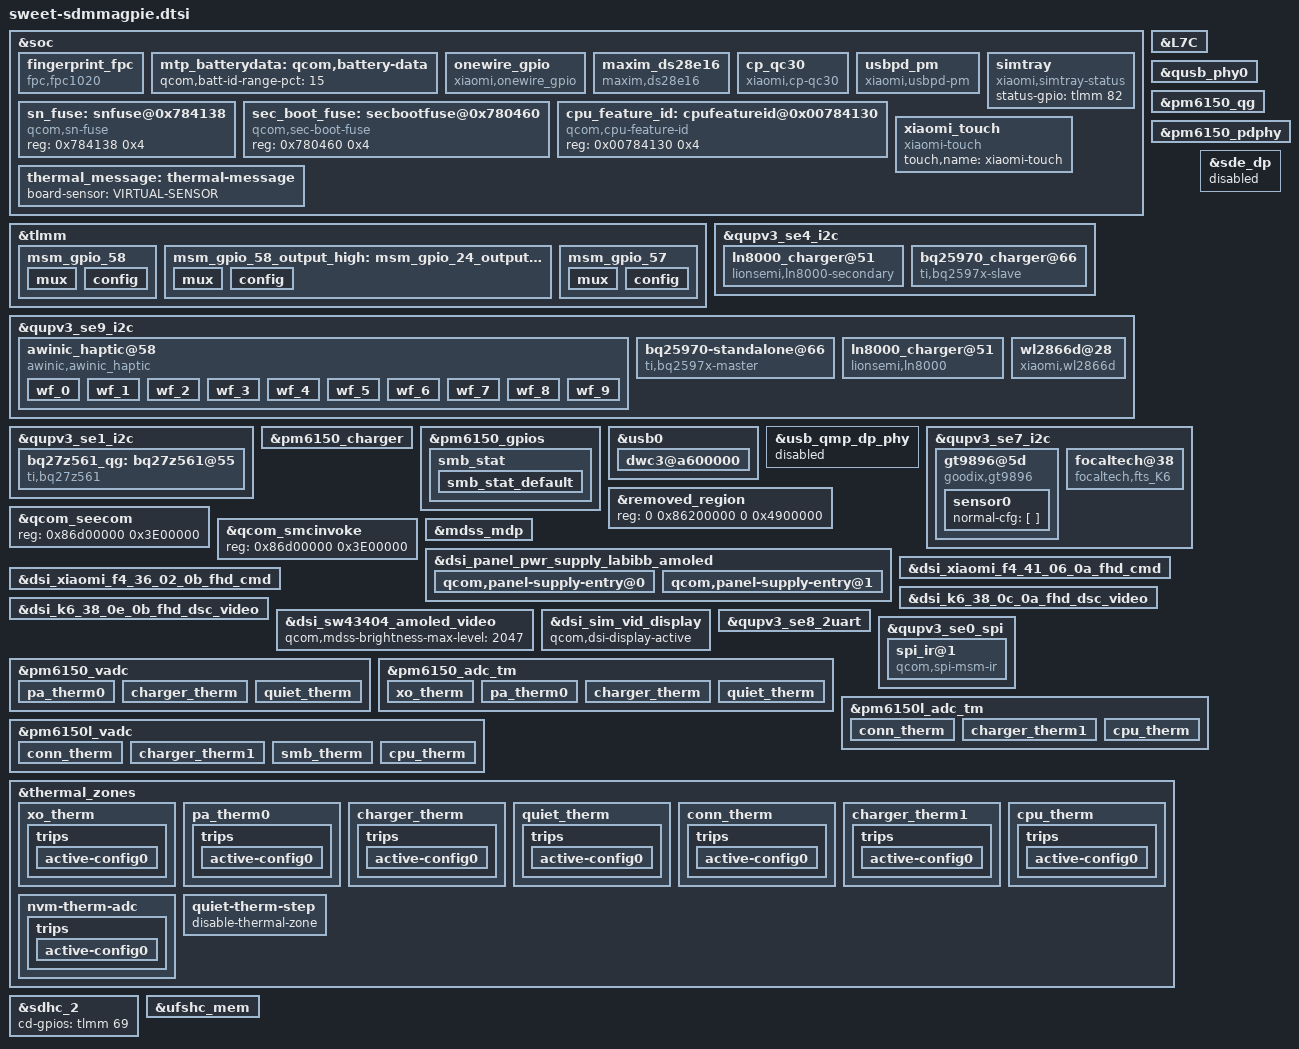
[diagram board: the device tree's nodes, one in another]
/*
this file is for attribution only of aquila
And public attribution of xiaomi platforms(like F3 and so and)
*/

#include "sweet-sdmmagpie-pinctrl.dtsi"
#include "xiaomi-sdmmagpie-common.dtsi"
#include "sweet-sdmmagpie-camera-sensor.dtsi"

&soc {
	/*
	touch_vddio_vreg: touch_vddio_vreg {
		compatible = "regulator-fixed";
		regulator-name = "disp_vddio_vreg";
		startup-delay-us = <4000>;
		enable-active-high;
		regulator-boot-on;
		gpio = <&tlmm 90 0>;
	};*/

	fingerprint_fpc {
		status = "ok";
		compatible = "fpc,fpc1020";
		interrupt-parent = <&tlmm>;
		interrupts = <57 0x0>;
		fpc,gpio_rst    = <&tlmm 58 0x0>;
		fpc,gpio_irq    = <&tlmm 57 0x0>;
		pinctrl-names = "fpc1020_reset_reset",
			"fpc1020_reset_active",
			"fpc1020_irq_active";

		pinctrl-0 = <&msm_gpio_58>;
		pinctrl-1 = <&msm_gpio_58_output_high>;
		pinctrl-2 = <&msm_gpio_57>;
	};

	mtp_batterydata: qcom,battery-data {
		qcom,batt-id-range-pct = <15>;
		#include "batterydata-K6-sunwoda-5020mah.dtsi"
		#include "batterydata-K6-nvt-5020mah.dtsi"
	};

	onewire_gpio: onewire_gpio{
		compatible = "xiaomi,onewire_gpio";
		label = "xm_onewire";
		xiaomi,version = <1>;
		xiaomi,ow_gpio = <&tlmm 91 0x00>;
		mi,onewire-gpio-cfg-addr = <0x0395B000 0x4>;
		pinctrl-names = "onewire_active", "onewire_sleep";
		pinctrl-0 = <&onewire_gpio_active>;
		pinctrl-1 = <&onewire_gpio_sleep>;
		status = "ok";
	};

	maxim_ds28e16: maxim_ds28e16{
		compatible = "maxim,ds28e16";
		label = "max_ds28e16";
		maxim,version = <1>;
		status = "ok";
	};

	cp_qc30 {
		compatible = "xiaomi,cp-qc30";
		status = "ok";
		mi,qc3-bat-volt-max = <4450>;
		mi,qc3-ffc-bat-volt-max = <4470>;
		mi,qc3-bat-curr-max = <5400>;
		mi,qc3-bus-volt-max = <12000>;
		mi,qc3-bus-curr-max = <2100>;
		mi,support-qc3p5-without-smb;
		mi,cp-sec-enable;
	};

	usbpd_pm {
		compatible = "xiaomi,usbpd-pm";
		status = "ok";
		mi,pd-bat-volt-max = <4450>;
		mi,pd-ffc-bat-volt-max = <4475>;
		mi,pd-bat-curr-max = <12000>;
		mi,pd-bus-volt-max = <12000>;
		mi,pd-bus-curr-max = <6100>;
		mi,pd-bus-curr-compensate = <300>;
		mi,cp-sec-enable;
	};

	simtray {
		compatible = "xiaomi,simtray-status";
		status-gpio = <&tlmm 82 0x00>;
	};

	sn_fuse: snfuse@0x784138 {
		compatible = "qcom,sn-fuse";
		reg = <0x784138 0x4>;
		reg-names = "sn-base";
	};

	sec_boot_fuse: secbootfuse@0x780460 {
		compatible = "qcom,sec-boot-fuse";
		reg = <0x780460  0x4>;
		reg-names = "sec-boot-base";
	};

	cpu_feature_id: cpufeatureid@0x00784130 {
		compatible = "qcom,cpu-feature-id";
		reg = <0x00784130  0x4>;
		reg-names = "cpu-feature-id";
	};
};

&L7C {
		regulator-min-microvolt = <3200000>;
		regulator-max-microvolt = <3200000>;
		qcom,init-voltage = <3200000>;
};

&tlmm {
	/* GPIO_58: FP_RESET_N */
	msm_gpio_58: msm_gpio_58 {
		mux {
			pins = "gpio58";
			function = "gpio";
		};
		config {
			pins = "gpio58";
			driver-strength = <2>;
			bias-disable;
			output-low;
		};
	};
	/* GPIO_58 : FP_RESET_N, state device active */
	msm_gpio_58_output_high: msm_gpio_24_output_high {
		mux {
			pins = "gpio58";
			function = "gpio";
		};
		config {
			pins = "gpio58";
			drive-strength = <2>;
			bias-disable;
			output-high;
		};
	};
	/* GPIO_57 : FP_INT_N */
	msm_gpio_57: msm_gpio_57 {
		mux {
			pins = "gpio57";
			function = "gpio";
		};
		config {
			pins = "gpio57";
			drive-strength = <2>;
			bias-pull-down;
		};
	};

};

&qusb_phy0 {
	qcom,qusb-phy-init-seq =
		/* <value reg_offset> */
		   <0x23 0x210 /* PWR_CTRL1 */
		    0x03 0x04  /* PLL_ANALOG_CONTROLS_TWO */
		    0x7c 0x18c /* PLL_CLOCK_INVERTERS */
		    0x80 0x2c  /* PLL_CMODE */
		    0x0a 0x184 /* PLL_LOCK_DELAY */
		    0x19 0xb4  /* PLL_DIGITAL_TIMERS_TWO */
		    0x40 0x194 /* PLL_BIAS_CONTROL_1 */
		    0x16 0x198 /* PLL_BIAS_CONTROL_2 */
		    0x21 0x214 /* PWR_CTRL2 */
		    0x08 0x220 /* IMP_CTRL1 */
		    0x58 0x224 /* IMP_CTRL2 */
		    0x07 0x240 /* TUNE1 */
		    0x29 0x244 /* TUNE2 */
		    0xca 0x248 /* TUNE3 */
		    0x07 0x24c /* TUNE4 */
		    0x03 0x250 /* TUNE5 */
		    0x30 0x23c /* CHG_CTRL2 */
		    0x22 0x210>; /* PWR_CTRL1 */
};

&qupv3_se4_i2c {
	status = "ok";
	ln8000_charger@51 {
		compatible = "lionsemi,ln8000-secondary";
		reg = <0x51>;
		/* bank <bit-idx> <flags: active-low> */
		//irq-gpios = <&tlmm 55 0x2002>;
        //interrupt-parent = <&tlmm>;
        //interrupts = <55 0x2002>;
        //pinctrl-names = "default";
        //pinctrl-0 = <&bq2597x_int_default &bq2597x_int_suspend>;
		ln8000_charger,irq_index = <296>;
		/* device configuration */
		ln8000_charger,bat-ovp-threshold = <4560>;
        ln8000_charger,bat-ovp-alarm-threshold = <4525>;
        ln8000_charger,bus-ovp-threshold = <13000>;
        ln8000_charger,bus-ovp-alarm-threshold = <11000>;
        ln8000_charger,bus-ocp-threshold = <3750>;
        ln8000_charger,bus-ocp-alarm-threshold = <3500>;
        ln8000_charger,ntc-alarm-cfg  = <226>;
		/* protection enable/disable flags
		 *   vbat-ovp-disable
		 *   vbat-reg-disable
		 *   iin-ocp-disable
		 *   iin-reg-disable
		 *   tbus-mon-disable
		 *   tbat-mon-disable
		 *   tdie-prot-disable
		 *   tdie-reg-disable
		 *   revcurr-prot-disable
		 */
		ln8000_charger,tdie-prot-disable;
        ln8000_charger,tbus-mon-disable;
        ln8000_charger,tbat-mon-disable;
        ln8000_charger,iin-ocp-disable;
        ln8000_charger,iin-reg-disable;
        ln8000_charger,tdie-reg-disable;
        ln8000_charger,vbat-reg-disable;
	};

	bq25970_charger@66 {
		compatible = "ti,bq2597x-slave";
		reg = <0x66>;

		interrupt-parent = <&tlmm>;
		interrupts = <56 0x2002>;
		pinctrl-names = "default_2";
		pinctrl-0 = <&bq2597x_2_int_default &bq2597x_2_int_suspend>;

		/*ti,bq2597x,bat-ovp-disable;*/
		ti,bq2597x,bat-ovp-alarm-disable;
		ti,bq2597x,bat-ocp-disable;
		ti,bq2597x,bat-ocp-alarm-disable;
		ti,bq2597x,bat-ucp-alarm-disable;
		ti,bq2597x,bat-ucp-disable;

		/*ti,bq2597x,bus-ovp-alarm-disable;
		ti,bq2597x,bus-ocp-disable;
		ti,bq2597x,bus-ocp-alarm-disable;*/
		ti,bq2597x,bat-therm-disable;
		ti,bq2597x,bus-therm-disable;
		ti,bq2597x,die-therm-disable;

		ti,bq2597x,bat-ovp-threshold = <4575>;
		ti,bq2597x,bat-ovp-alarm-threshold = <4500>;
		//ti,bq2597x,bat-ocp-threshold = <5000>;
		//ti,bq2597x,bat-ocp-alarm-threshold = <4500>;

		ti,bq2597x,bus-ovp-threshold = <12000>;
		ti,bq2597x,bus-ovp-alarm-threshold = <11000>;
		ti,bq2597x,bus-ocp-threshold = <3500>;
		ti,bq2597x,bus-ocp-alarm-threshold = <3200>;

		//ti,bq2597x,bat-ucp-alarm-threshold = <2000>;

		ti,bq2597x,bat-therm-threshold = <0x15>;/*4.1%*/
		ti,bq2597x,bus-therm-threshold = <0x15>;/*4.1%*/
		ti,bq2597x,die-therm-threshold = <145>;

		ti,bq2597x,ac-ovp-threshold = <14>;
		//ti,bq2597x,sense-resistor-mohm = <2>;
	};
};

&qupv3_se9_i2c {
	status = "ok";
	qcom,clk-freq-out = <400000>;
	qcom,clk-freq-in = <400000>;
	awinic_haptic@58 {
		compatible = "awinic,awinic_haptic";
		reg = <0x5A>;
		aw8622x_i2c_addr = < 0x58 >;
		reset-gpio = <&tlmm 4 0>;
		irq-gpio = <&pm6150l_gpios  10 0>;
		pinctrl-names = "awinic_reset_reset","awinic_reset_active","awinic_interrupt_active";
		pinctrl-0 = <&awinic_gpio_reset>;
		pinctrl-1 = <&awinic_gpio_reset_output_high>;
		pinctrl-2 = <&awinic_gpio_int>;
		/*---------------------aw8624_dts_info---------------------*/
		aw8624_vib_f0_pre = < 2050 >;
		aw8624_vib_f0_cali_percen = < 7 >;
		aw8624_vib_cont_drv_lev = < 106 >;
		aw8624_vib_cont_drv_lvl_ov = < 155 >;
		aw8624_vib_cont_td = < 0xF06C >;
		aw8624_vib_cont_zc_thr = < 0x08F8 >;
		aw8624_vib_cont_num_brk = < 3 >;
		aw8624_vib_f0_coeff = < 260 >; /*Don't modify it*/
		aw8624_vib_duration_time = < 15 60 0 0 0 >;
		aw8624_vib_brake_ram_config = < 1 1 90 60 20 3 1 3 1 1 90 60 30 5 1 3 0 0 50 40 25 0 5 3 >;
		aw8624_vib_brake_cont_config = < 1 1 90 42 20 5 2 2 0 0 0 0 0 0 0 0 0 0 0 0 0 0 0 0 >;
		aw8624_vib_f0_trace_parameter = < 9 5 1 15 >;
		aw8624_vib_bemf_config = < 0 8 3 0xf8 >;
		aw8624_vib_sw_brake = < 0x2c >;
		aw8624_vib_wavseq = < 0 1 1 2 0 0 0 0 0 0 0 0 0 0 0 0 >; /*wavseq1-seq8 0x07-0x0E*/
		aw8624_vib_wavloop = < 0 6 1 15 0 0 0 0 0 0>;/*loop1-mainloog 0x0f-0x13*/
		aw8624_vib_td_brake = < 42720 42720 42720 >; /*level0 level1 level2*/
		aw8624_vib_tset = < 0x11 >;
		aw8624_vib_func_parameter1 = < 1 >;
		aw8624_vib_gain_flag = < 1 >;
		aw8624_vib_r_spare = < 0x68 >;
		aw8624_vib_bstdbg = < 0x30 0xeb 0xd4 0 0 0 >;
		/*---------------------aw8622x_dts_info---------------------*/
		aw8622x_vib_mode = < 0 >; /* mode: RAM mode->0; CONT mode->1 */
		aw8622x_vib_f0_pre = < 2050 >;
		aw8622x_vib_f0_cali_percen = < 7 >;
		aw8622x_vib_cont_drv1_lvl = < 0x7F >;
		aw8622x_vib_cont_drv2_lvl = < 0x3A >;
		aw8622x_vib_cont_brk_time = < 0x06 >;
		aw8622x_vib_cont_tset = < 0x06 >;
		aw8622x_vib_cont_bemf_set = < 0x02 >;
		aw8622x_vib_cont_drv_width = < 0x56 >;
		aw8622x_vib_cont_wait_num = < 0x06 >;
		aw8622x_vib_cont_brk_gain = < 0x08 >;
		aw8622x_vib_cont_drv1_time = < 0x08 >;
		aw8622x_vib_cont_drv2_time = < 0x14 >;
		aw8622x_vib_cont_track_margin = < 0x0F >;
		aw8622x_vib_sine_array = < 0x05 0xB2 0xFF 0xEF >; /* SIN_H SIN_L COS_H COS_L*/
		aw8622x_vib_d2s_gain = < 0x05 >;
		aw8622x_vib_prctmode = < 0x2D 0x3E 0x3F >;
		/*---------------------common_dts_info---------------------*/
		vib_effect_id_boundary = < 10 >;
		vib_effect_max = < 170 >;
		vib_rtp_time = < 20 20 20 20 20 20 20 20 20 30
				 40 50 60 70 80 90 100 110 120 130
				 140 150 160 170 180 190 200 210 220 230
				 240 250 260 270 280 290 300 310 320 330
				 20 20 20 20 20 20 20 20 20 20
				 20 20 20 20 20 20 20 20 20 20
				 20 20 20 20 20 20 20 20 20 20
				 20 20 20 20 20 20 20 20 20 20
				 20 20 20 20 20 20 20 20 20 20
				 20 20 20 20 20 20 20 20 20 20
				 20 20 20 20 20 20 20 20 20 20
				 20 20 20 20 20 20 20 20 20 20
				 20 20 20 20 20 20 20 20 20 20
				 20 20 20 20 20 20 20 20 20 20
				 20 20 20 20 20 20 20 20 20 20
				 20 20 20 20 20 20 20 20 20 20
				 20 20 20 20 20 20 20 20 20 20
				 20 20 20 20 20 >;
		status = "okay";
		wf_0 {
			//CLICK
			qcom,effect-id = <0>;
			qcom,wf-vmax-mv = <3600>;
			qcom,wf-pattern = [3e 3e];
			qcom,wf-brake-pattern = [02 01 00 00];
			qcom,wf-play-rate-us = <20000>;
		};
		wf_1 {
			//DOUBLE CLICK
			qcom,effect-id = <1>;
			qcom,wf-vmax-mv = <3600>;
			qcom,wf-pattern = [7e 3e];
			qcom,wf-brake-pattern = [03 01 00 00];
			qcom,wf-play-rate-us = <20000>;
		};
		wf_2 {
			//TICK
			qcom,effect-id = <2>;
			qcom,wf-vmax-mv = <3600>;
			qcom,wf-pattern = [7e 3e];
			qcom,wf-brake-pattern = [02 01 00 00];
			qcom,wf-play-rate-us = <20000>;
		};
		wf_3 {
			//THUD
			qcom,effect-id = <3>;
			qcom,wf-vmax-mv = <3600>;
			qcom,wf-pattern = [3e 3e];
			qcom,wf-brake-pattern = [02 01 00 00];
			qcom,wf-play-rate-us = <20000>;
		};
		wf_4 {
			//POP
			qcom,effect-id = <4>;
			qcom,wf-vmax-mv = <3600>;
			qcom,wf-pattern = [3e 3e];
			qcom,wf-brake-pattern = [02 01 00 00];
			qcom,wf-play-rate-us = <28000>;
		};
		wf_5 {
			//HEAVY CLICK
			qcom,effect-id = <5>;
			qcom,wf-vmax-mv = <3600>;
			qcom,wf-pattern = [7e 7e 7e];
			qcom,wf-brake-pattern = [03 03 01 00];
			qcom,wf-play-rate-us = <20000>;
		};
		wf_6 {
			//id 6
			qcom,effect-id = <6>;
			qcom,wf-vmax-mv = <3600>;
			qcom,wf-pattern = [3e 3e];
			qcom,wf-brake-pattern = [02 01 00 00];
			qcom,wf-play-rate-us = <20000>;
		};
		wf_7 {
			//id 7
			qcom,effect-id = <7>;
			qcom,wf-vmax-mv = <3600>;
			qcom,wf-pattern = [3e 3e];
			qcom,wf-brake-pattern = [02 01 00 00];
			qcom,wf-play-rate-us = <20000>;
		};
		wf_8 {
			//id 8
			qcom,effect-id = <8>;
			qcom,wf-vmax-mv = <3600>;
			qcom,wf-pattern = [3e 3e];
			qcom,wf-brake-pattern = [02 01 00 00];
			qcom,wf-play-rate-us = <20000>;
		};
		wf_9 {
			//id 9
			qcom,effect-id = <9>;
			qcom,wf-vmax-mv = <3600>;
			qcom,wf-pattern = [3e 3e];
			qcom,wf-brake-pattern = [02 01 00 00];
			qcom,wf-play-rate-us = <20000>;
		};
	};

	bq25970-standalone@66 {
		compatible = "ti,bq2597x-master";
		reg = <0x66>;

		interrupt-parent = <&tlmm>;
		interrupts = <55 0x2002>;
		pinctrl-names = "default";
		pinctrl-0 = <&bq2597x_int_default &bq2597x_int_suspend>;

		/*ti,bq2597x,bat-ovp-disable;*/
		ti,bq2597x,bat-ovp-alarm-disable;
		ti,bq2597x,bat-ocp-disable;
		ti,bq2597x,bat-ocp-alarm-disable;
		ti,bq2597x,bat-ucp-alarm-disable;
		ti,bq2597x,bat-ucp-disable;

		/*ti,bq2597x,bus-ovp-alarm-disable;
		ti,bq2597x,bus-ocp-disable;
		ti,bq2597x,bus-ocp-alarm-disable;*/
		ti,bq2597x,bat-therm-disable;
		ti,bq2597x,bus-therm-disable;
		ti,bq2597x,die-therm-disable;

		ti,bq2597x,bat-ovp-threshold = <4575>;
		ti,bq2597x,bat-ovp-alarm-threshold = <4500>;
		//ti,bq2597x,bat-ocp-threshold = <5000>;
		//ti,bq2597x,bat-ocp-alarm-threshold = <4500>;

		ti,bq2597x,bus-ovp-threshold = <12000>;
		ti,bq2597x,bus-ovp-alarm-threshold = <11000>;
		ti,bq2597x,bus-ocp-threshold = <3500>;
		ti,bq2597x,bus-ocp-alarm-threshold = <3200>;

		//ti,bq2597x,bat-ucp-alarm-threshold = <2000>;

		ti,bq2597x,bat-therm-threshold = <0x15>;/*4.1%*/
		ti,bq2597x,bus-therm-threshold = <0x15>;/*4.1%*/
		ti,bq2597x,die-therm-threshold = <145>;

		ti,bq2597x,ac-ovp-threshold = <14>;
		//ti,bq2597x,sense-resistor-mohm = <2>;
	};

	ln8000_charger@51 {
		compatible = "lionsemi,ln8000";
		reg = <0x51>;
		/* bank <bit-idx> <flags: active-low> */
		//irq-gpios = <&tlmm 55 0x2002>;

                //interrupt-parent = <&tlmm>;
                //interrupts = <55 0x2002>;
                //pinctrl-names = "default";
                //pinctrl-0 = <&bq2597x_int_default &bq2597x_int_suspend>;
		ln8000_charger,irq_index = <296>;
		/* device configuration */
		ln8000_charger,bat-ovp-threshold = <4560>;
        ln8000_charger,bat-ovp-alarm-threshold = <4525>;
        ln8000_charger,bus-ovp-threshold = <13000>;
        ln8000_charger,bus-ovp-alarm-threshold = <11000>;
        ln8000_charger,bus-ocp-threshold = <3750>;
        ln8000_charger,bus-ocp-alarm-threshold = <3500>;
        ln8000_charger,ntc-alarm-cfg  = <226>;
		/* protection enable/disable flags
		 *   vbat-ovp-disable
		 *   vbat-reg-disable
		 *   iin-ocp-disable
		 *   iin-reg-disable
		 *   tbus-mon-disable
		 *   tbat-mon-disable
		 *   tdie-prot-disable
		 *   tdie-reg-disable
		 *   revcurr-prot-disable
		 */
		ln8000_charger,tdie-prot-disable;
        ln8000_charger,tbus-mon-disable;
        ln8000_charger,tbat-mon-disable;
        ln8000_charger,iin-ocp-disable;
        ln8000_charger,iin-reg-disable;
        ln8000_charger,tdie-reg-disable;
        ln8000_charger,vbat-reg-disable;
	};

    wl2866d@28 {
        compatible = "xiaomi,wl2866d";
        reg = <0x28>;
        vin1-supply = <&S8C>;
        vin1-voltage-level = <1350000  1350000>;
        vin2-supply = <&BOB>;
        vin2-voltage-level = <3300000  3300000>;
        en-gpio =  <&tlmm 30 0>;
        status = "ok";
    };
};

&pm6150_qg {
	qcom,battery-data = <&mtp_batterydata>;
	qcom,vbatt-cutoff-mv = <3400>;
	qcom,vbatt-low-mv = <3500>;
	qcom,vbatt-low-cold-mv = <3800>;
	qcom,vbatt-empty-mv = <3100>;
	qcom,vbatt-empty-cold-mv = <3000>;
	qcom,s3-entry-fifo-length = <2>;
	qcom,s3-entry-ibat-ua = <25000>;
	qcom,s3-exit-ibat-ua = <45000>;
	qcom,qg-iterm-ma = <350>;
	qcom,hold-soc-while-full;
	qcom,linearize-soc;
	qcom,cl-feedback-on;
	qcom,shutdown-soc-threshold = <10>;
	qcom,qg-ext-sns;
	mi,software-optimize-ffc-qg-iterm;
	qcom,shutdown-delay-enable;
	qcom,tcss-enable;
	qcom,tcss-entry-soc = <90>;
	qcom,bass-enable;
	qcom,esr-disable;

	qcom,soc_decimal_rate = <
		0  32
		10 30
		20 28
		30 28
		40 28
		50 28
		60 28
		70 28
		80 28
		90 26
		95 10
		99 5>;
};

&qupv3_se1_i2c {
	status = "ok";
    bq27z561_qg: bq27z561@55 {
        #io-channel-cells = <1>;
        compatible = "ti,bq27z561";
        bq,shutdown-delay-enable;
        reg = <0x55>;
        bq,soc_decimal_rate = <
				0  32
				10 30
				20 28
				30 28
				40 28
				50 28
				60 28
				70 28
				80 28
				90 26
				95 10
				99 5>;
	};
};

&pm6150_charger {
	io-channels = <&pm6150_vadc ADC_USB_IN_V_16>,
		      <&pm6150_vadc ADC_USB_IN_I>,
		      <&pm6150_vadc ADC_CHG_TEMP>,
		      <&pm6150_vadc ADC_DIE_TEMP>,
		      <&pm6150l_vadc ADC_AMUX_THM1_PU2>,
		      <&pm6150_vadc ADC_SBUx>,
		      <&pm6150_vadc ADC_VPH_PWR>;
	io-channel-names = "usb_in_voltage",
			   "usb_in_current",
			   "chg_temp",
			   "die_temp",
			   "conn_temp",
			   "sbux_res",
			   "vph_voltage";
	qcom,battery-data = <&mtp_batterydata>;
	qcom,usb-icl-ua = <3000000>;
	qcom,otg-cl-ua = <1500000>;
	qcom,fcc-max-ua = <12000000>;
	mi,fcc-batt-unverify-ua = <12200000>;
	qcom,fv-max-uv = <4480000>;
	qcom,auto-recharge-vbat-mv = <4400>;
	qcom,chg-term-src = <1>;
	qcom,chg-term-current-ma = <(-210)>;
	qcom,sec-charger-config = <0>;
	qcom,disable-sw-thermal-regulation;

	qcom,thermal-mitigation
				= <12400000 12000000 11500000 11000000 10500000 10000000 9500000
				   9000000  8500000  8000000  7500000  7000000  6500000  6000000
				   5500000  5000000  4500000  4000000  3500000  3000000  2500000
				   2000000  1500000  1000000  500000   0000000  0000000  0000000>;
	qcom,thermal-mitigation-icl
				= <12400000 12000000 11500000 11000000 10500000 10000000 9500000
				   9000000  8500000  8000000  7500000  7000000  6500000  6000000
				   5500000  5000000  4500000  4000000  3500000  3000000  2500000
				   2000000  1500000  1000000  500000   0000000  0000000  0000000>;
	qcom,thermal-mitigation-dcp
				= <12400000 12000000 11500000 11000000 10500000 10000000 9500000
				   9000000  8500000  8000000  7500000  7000000  6500000  6000000
				   5500000  5000000  4500000  4000000  3500000  3000000  2500000
				   2000000  1500000  1000000  500000   0000000  0000000  0000000>;
	qcom,thermal-mitigation-qc2
				= <12400000 12000000 11500000 11000000 10500000 10000000 9500000
				   9000000  8500000  8000000  7500000  7000000  6500000  6000000
				   5500000  5000000  4500000  4000000  3500000  3000000  2500000
				   2000000  1500000  1000000  500000   0000000  0000000  0000000>;
	qcom,thermal-fcc-qc3-normal
				= <12400000 12000000 11500000 11000000 10500000 10000000 9500000
				   9000000  8500000  8000000  7500000  7000000  6500000  6000000
				   5500000  5000000  4500000  4000000  3500000  3000000  2500000
				   2000000  1500000  1000000  500000   0000000  0000000  0000000>;
	qcom,thermal-fcc-qc3-cp
				= <12400000 12000000 11500000 11000000 10500000 10000000 9500000
				   9000000  8500000  8000000  7500000  7000000  6500000  6000000
				   5500000  5000000  4500000  4000000  3500000  3000000  2500000
				   2000000  1500000  1000000  500000   0000000  0000000  0000000>;
	qcom,thermal-mitigation-pd-base
				= <12400000 12000000 11500000 11000000 10500000 10000000 9500000
				   9000000  8500000  8000000  7500000  7000000  6500000  6000000
				   5500000  5000000  4500000  4000000  3500000  3000000  2500000
				   2000000  1500000  1000000  500000   0000000  0000000  0000000>;
	qcom,thermal-fcc-pps-cp
				= <12400000 12000000 11500000 11000000 10500000 10000000 9500000
				   9000000  8500000  8000000  7500000  7000000  6500000  6000000
				   5500000  5000000  4500000  4000000  3500000  3000000  2500000
				   2000000  1500000  1000000  500000   0000000  0000000  0000000>;

	dpdm-supply = <&qusb_phy0>;
	qcom,reg-dump-enable;
	qcom,sw-jeita-enable;
	qcom,step-charging-enable;
	/*qcom,distinguish-qc-class-ab;*/
	qcom,lpd-disable;
	qcom,usbpd-phandle = <&pm6150_pdphy>;
	qcom,disable-suspend-on-collapse;
	mi,use-bq-pump;
	mi,support-ffc;
	mi,early-status-report;
	mi,support-qc3p5-without-smb;
	mi,ffc-low-tbat = <150>;
	mi,ffc-high-tbat = <480>;
};

&pm6150_pdphy {
	mi,non-qcom-pps-ctrl;
	mi,pd_curr_limit = <1>;
	mi,pd_max_curr_limit = <6200000>;
	mi,limit_pd_unverified_pps_vbus = <1>;
	mi,pd_unverified_pps_max_vbus_limit = <9500000>;
};

&pm6150_gpios {
	smb_stat {
		smb_stat_default: smb_stat_default {
			pins = "gpio3";
			function = "normal";
			input-enable;
			bias-pull-up;
			qcom,pull-up-strength = <PMIC_GPIO_PULL_UP_30>;
			power-source = <0>;
		};
	};
/*
	vbus_disable {
		vbus_disable_suspend: usb_vbus_suspend {
			pins = "gpio4";
			function = "normal";
			output-low;
			power-source = <0>;
		};
	};
*/
};

&usb0 {
	dwc3@a600000 {
		usb-phy = <&qusb_phy0>, <&usb_nop_phy>;
		maximum-speed = "high-speed";
	};
};

&usb_qmp_dp_phy {
	status = "disabled";
};

&qupv3_se7_i2c{
	status = "ok";
	gt9896@5d {
		compatible = "goodix,gt9896";
		reg = <0x5d>;
		status = "ok";
		interrupt-parent = <&tlmm>;
		interrupts = <9 0x0>;
		pinctrl-names = "pmx_ts_active", "pmx_ts_suspend";
		pinctrl-0 = <&ts_active>;
		pinctrl-1 = <&ts_int_suspend &ts_reset_suspend>;
		vtouch-supply = <&pm6150l_l7>;
		goodix,vdd-gpio = <&tlmm 90 0x0>;
		goodix,avdd-name = "vtouch";
		goodix,reset-gpio = <&tlmm 8 0x0>;
		goodix,irq-gpio = <&tlmm 9 0x0>;
		goodix,irq-flags = <2>; /* 1:rising, 2:falling;*/
		goodix,panel-max-id = <10>;
		goodix,panel-max-x = <8639>;
		goodix,panel-max-y = <19199>;
		goodix,panel-max-w = <256>;
		goodix,panel-max-p = <256>;
		/*goodix,input-max-x = <1079>; */
		/*goodix,input-max-y = <2399>; */
		/*goodix,panel-key-map = <158 172 217>;*/ /*BACK,HOMEPAGE,SEARCH*/
		goodix,power-on-delay-us = <100>; /*0.1ms*/
		goodix,power-off-delay-us = <5000>;
		goodix,firmware-version = "6885b1";
		goodix,config-version = "6885v9c";
		/*goodix,swap-axis;*/
		/*goodix,x2x;*/
		/*goodix,y2y;*/
		/*goodix,pen-enable;*/
		/*goodix,key-of-pen = <331 332>;*//*BTN_STYLUS, BTN_STYLUS2*/
		tpd-filter-enable = <1>;
		tpd-filter-pixel-density = <161>;
		tpd-filter-custom-prameters = <0 0 0 0 0 0 0 0 0 0 0 0>;
		tpd-filter-custom-speed = <0 0 0>;
		/*new touch faeature default param*/
		goodix,touch-game-param-config1 = <3 3 1 3>;
		goodix,touch-game-param-config2 = <2 4 2 3>;
		goodix,touch-game-param-config3 = <4 4 3 1>;
		sensor0 {
			normal-cfg = [
			];
		};
	};
	focaltech@38{
		compatible = "focaltech,fts_K6";
		reg = <0x38>;
		interrupt-parent = <&tlmm>;
		interrupts = <9 0x0>;
		vdd-supply = <&pm6150l_l7>;
		vcc_i2c-supply = <&tlmm 90 0x0>;
		focaltech,reset-gpio = <&tlmm 8 0x0>;
		focaltech,irq-gpio = <&tlmm 9 0x0>;
		focaltech,max-touch-number = <10>;
		focaltech,display-coords =  <0 0 1079 2399>;
		pinctrl-names = "pmx_ts_active","pmx_ts_suspend","pmx_ts_release";
		pinctrl-0 = <&ts_active>;
		pinctrl-1 = <&ts_int_suspend &ts_reset_suspend>;
		pinctrl-2 = <&ts_release>;
		focaltech,touch-range-array = <1 5 10 15 20>;
		focaltech,touch-def-array = <3 3 3 3>;
		focaltech,touch-expert-array = <10 10 10 10
						20 20 15 10
						20 20 20 10>;

		/*
		focaltech,have-key;
		focaltech,key-number = <3>;
		focaltech,keys = <139 102 158>;
		focaltech,key-x-coords = <200 600 800>;
		focaltech,key-y-coords = <2000 2000 2000>;
		*/
	};
};

&soc {
	xiaomi_touch {
		compatible = "xiaomi-touch";
		status = "ok";
		touch,name = "xiaomi-touch";
	};
	thermal_message: thermal-message {
		board-sensor = "VIRTUAL-SENSOR";
	};
};

/* Enlarge TZ memory size to 62M */
&removed_region {
	reg = <0 0x86200000 0 0x4900000>;
};

&qcom_seecom {
	reg = <0x86d00000 0x3E00000>;
};

&qcom_smcinvoke {
	reg = <0x86d00000 0x3E00000>;
};

&sde_dp {
	status = "disabled";
	qcom,dp-usbpd-detection = <&pm6150_pdphy>;
};

&mdss_mdp {
	connectors = <&sde_rscc &sde_wb &sde_dsi &sde_dsi1>;
};

&dsi_panel_pwr_supply_labibb_amoled {

	qcom,panel-supply-entry@0 {
		reg = <0>;
		qcom,supply-name = "vddio";
		qcom,supply-min-voltage = <1900000>;
		qcom,supply-max-voltage = <1900000>;
		qcom,supply-enable-load = <32000>;
		qcom,supply-disable-load = <80>;
		qcom,supply-pre-off-sleep = <20>;
	};

	qcom,panel-supply-entry@1 {
		reg = <1>;
		qcom,supply-name = "vdda-3p3";
		qcom,supply-min-voltage = <3000000>;
		qcom,supply-max-voltage = <3000000>;
		qcom,supply-enable-load = <13200>;
		qcom,supply-disable-load = <80>;
		qcom,supply-pre-off-sleep = <10>;
	};
};

&dsi_xiaomi_f4_41_06_0a_fhd_cmd {
	qcom,panel-supply-entries = <&dsi_panel_pwr_supply_labibb_amoled>;
	qcom,mdss-dsi-bl-pmic-control-type = "bl_ctrl_dcs";
	qcom,mdss-dsi-bl-min-level = <2>;
	qcom,mdss-dsi-bl-max-level = <2047>;
	qcom,mdss-dsi-mode-sel-gpio-state = "single_port";
	//qcom,panel-mode-gpio = <&tlmm 7 0>;
	qcom,platform-te-gpio = <&tlmm 10 0>;
	qcom,platform-reset-gpio = <&pm6150l_gpios 9 0>;
};

&dsi_xiaomi_f4_36_02_0b_fhd_cmd {
	qcom,panel-supply-entries = <&dsi_panel_pwr_supply_labibb_amoled>;
	qcom,mdss-dsi-bl-pmic-control-type = "bl_ctrl_dcs";
	qcom,mdss-dsi-bl-min-level = <2>;
	qcom,mdss-dsi-bl-max-level = <2047>;
	qcom,mdss-dsi-mode-sel-gpio-state = "single_port";
	//qcom,panel-mode-gpio = <&tlmm 7 0>;
	qcom,platform-te-gpio = <&tlmm 10 0>;
	qcom,platform-reset-gpio = <&pm6150l_gpios 9 0>;
};

&dsi_k6_38_0c_0a_fhd_dsc_video {
	qcom,panel-supply-entries = <&dsi_panel_pwr_supply_labibb_amoled>;
	qcom,mdss-dsi-bl-pmic-control-type = "bl_ctrl_dcs";
	qcom,mdss-dsi-bl-min-level = <4>;
	qcom,mdss-dsi-bl-max-level = <2047>;
	qcom,mdss-brightness-max-level = <2047>;
	qcom,mdss-dsi-mode-sel-gpio-state = "single_port";
	//qcom,platform-en-gpio = <&tlmm 30 0>;
	qcom,platform-te-gpio = <&tlmm 10 0>;
	qcom,platform-reset-gpio = <&pm6150l_gpios 9 0>;
};

&dsi_k6_38_0e_0b_fhd_dsc_video {
	qcom,panel-supply-entries = <&dsi_panel_pwr_supply_labibb_amoled>;
	qcom,mdss-dsi-bl-pmic-control-type = "bl_ctrl_dcs";
	qcom,mdss-dsi-bl-min-level = <4>;
	qcom,mdss-dsi-bl-max-level = <2047>;
	qcom,mdss-brightness-max-level = <2047>;
	qcom,mdss-dsi-mode-sel-gpio-state = "single_port";
	//qcom,platform-en-gpio = <&tlmm 30 0>;
	qcom,platform-te-gpio = <&tlmm 10 0>;
	qcom,platform-reset-gpio = <&pm6150l_gpios 9 0>;
};

&dsi_sw43404_amoled_video {
	qcom,mdss-brightness-max-level = <2047>;
};

&dsi_sim_vid_display {
	qcom,dsi-display-active;
};

&qupv3_se8_2uart {
	status = "ok";
};

&qupv3_se0_spi {
	#address-cells = <1>;
	#size-cells = <0>;
		qcom,infinite-mode = <0>;
		qcom,usb-bam;
		qcom,rt-priority;
		qcom,use-pinctrl;
		qcom,ver-reg-exists;
		qcom,bam-consumer-pipe-index = <6>;
		qcom,bam-producer-pipe-index = <7>;
		qcom,master-id = <84>;
		status = "ok";
		spi_ir@1 {
			compatible = "qcom,spi-msm-ir";
			reg = <1>;
			spi-max-frequency = <50000000>;
			spi-cpol;
			status = "ok";
			};
};

&sde_dp {
        pinctrl-names = "mdss_dp_active", "mdss_dp_sleep";
        pinctrl-0 = <&sde_dp_aux_active &sde_dp_usbplug_cc_active>;
        pinctrl-1 = <&sde_dp_aux_suspend &sde_dp_usbplug_cc_suspend>;
        qcom,aux-en-gpio = <&tlmm 42 0>;
        qcom,aux-sel-gpio = <&tlmm 33 0>;
        qcom,dp-gpio-aux-switch;
};
&pm6150_vadc {
	pa_therm0 {
		reg = <ADC_AMUX_THM2_PU2>;
		label = "pa_therm0";
		qcom,ratiometric;
		qcom,hw-settle-time = <200>;
		qcom,pre-scaling = <1 1>;
	};

	charger_therm {
		reg = <ADC_AMUX_THM3_PU2>;
		label = "charger_therm";
		qcom,ratiometric;
		qcom,hw-settle-time = <200>;
		qcom,pre-scaling = <1 1>;
	};

	quiet_therm {
		reg = <ADC_AMUX_THM4_PU2>;
		label = "quiet_therm";
		qcom,ratiometric;
		qcom,hw-settle-time = <200>;
		qcom,pre-scaling = <1 1>;
	};
};

&pm6150_adc_tm {
	io-channels = <&pm6150_vadc ADC_XO_THERM_PU2>,
			<&pm6150_vadc ADC_AMUX_THM2_PU2>,
			<&pm6150_vadc ADC_AMUX_THM3_PU2>,
			<&pm6150_vadc ADC_AMUX_THM4_PU2>;

	/* Channel nodes */
	xo_therm {
		reg = <ADC_XO_THERM_PU2>;
		qcom,ratiometric;
		qcom,hw-settle-time = <200>;
	};

	pa_therm0 {
		reg = <ADC_AMUX_THM2_PU2>;
		qcom,ratiometric;
		qcom,hw-settle-time = <200>;
	};

	charger_therm {
		reg = <ADC_AMUX_THM3_PU2>;
		qcom,ratiometric;
		qcom,hw-settle-time = <200>;
	};

	quiet_therm {
		reg = <ADC_AMUX_THM4_PU2>;
		qcom,ratiometric;
		qcom,hw-settle-time = <200>;
	};
};

&pm6150l_vadc {
	conn_therm {
		reg = <ADC_AMUX_THM1_PU2>;
		label = "conn_therm";
		qcom,ratiometric;
		qcom,hw-settle-time = <200>;
		qcom,pre-scaling = <1 1>;
	};

	charger_therm1 {
		reg = <ADC_AMUX_THM2_PU2>;
		label = "charger_therm1";
		qcom,ratiometric;
		qcom,hw-settle-time = <200>;
		qcom,pre-scaling = <1 1>;
	};

	smb_therm {
		reg = <ADC_AMUX_THM2>;
		label = "smb_therm";
		qcom,hw-settle-time = <200>;
		qcom,pre-scaling = <1 1>;
	};

	cpu_therm {
		reg = <ADC_AMUX_THM3_PU2>;
		label = "cpu_therm";
		qcom,ratiometric;
		qcom,hw-settle-time = <200>;
		qcom,pre-scaling = <1 1>;
	};
/*
	nvm_therm {
		reg = <ADC_GPIO4_PU2>;
		label = "nvm_therm";
		qcom,ratiometric;
		qcom,hw-settle-time = <200>;
		qcom,pre-scaling = <1 1>;
	};
*/
};

&pm6150l_adc_tm {
	io-channels = <&pm6150l_vadc ADC_AMUX_THM1_PU2>,
                       <&pm6150l_vadc ADC_AMUX_THM2_PU2>,
			<&pm6150l_vadc ADC_AMUX_THM3_PU2>;

	/* Channel nodes */
	conn_therm {
		reg = <ADC_AMUX_THM1_PU2>;
		qcom,ratiometric;
		qcom,hw-settle-time = <200>;
	};

	charger_therm1 {
		reg = <ADC_AMUX_THM2_PU2>;
		qcom,ratiometric;
		qcom,hw-settle-time = <200>;
	};

	cpu_therm {
		reg = <ADC_AMUX_THM3_PU2>;
		qcom,ratiometric;
		qcom,hw-settle-time = <200>;
	};
/*
	nvm_therm {
		reg = <ADC_GPIO4_PU2>;
		qcom,ratiometric;
		qcom,hw-settle-time = <200>;
	};
*/
};

&thermal_zones {

	xo_therm {
		polling-delay-passive = <0>;
		polling-delay = <0>;
		thermal-governor = "user_space";
		thermal-sensors = <&pm6150_adc_tm ADC_XO_THERM_PU2>;
		trips {
			active-config0 {
				temperature = <125000>;
				hysteresis = <1000>;
				type = "passive";
			};
		};
	};

	pa_therm0 {//place to modem pa nearby
		polling-delay-passive = <0>;
		polling-delay = <0>;
		thermal-governor = "user_space";
		thermal-sensors = <&pm6150_adc_tm ADC_AMUX_THM2_PU2>;
		trips {
			active-config0 {
				temperature = <125000>;
				hysteresis = <1000>;
				type = "passive";
			};
		};
	};

	charger_therm {//place to cpu nearby
		polling-delay-passive = <0>;
		polling-delay = <0>;
		thermal-governor = "user_space";
		thermal-sensors = <&pm6150_adc_tm ADC_AMUX_THM3_PU2>;
		trips {
			active-config0 {
				temperature = <125000>;
				hysteresis = <1000>;
				type = "passive";
			};
		};
	};

	quiet_therm {//place to quiet place
		polling-delay-passive = <0>;
		polling-delay = <0>;
		thermal-governor = "user_space";
		thermal-sensors = <&pm6150_adc_tm ADC_AMUX_THM4_PU2>;
		trips {
			active-config0 {
				temperature = <125000>;
				hysteresis = <1000>;
				type = "passive";
			};
		};
	};

	conn_therm {
		polling-delay-passive = <0>;
		polling-delay = <0>;
		thermal-governor = "user_space";
		thermal-sensors = <&pm6150l_adc_tm ADC_AMUX_THM1_PU2>;
		trips {
			active-config0 {
				temperature = <125000>;
				hysteresis = <1000>;
				type = "passive";
			};
		};
	};

	charger_therm1 {//place to charger IC
		polling-delay-passive = <0>;
		polling-delay = <0>;
		thermal-governor = "user_space";
		thermal-sensors = <&pm6150l_adc_tm ADC_AMUX_THM2_PU2>;
		trips {
			active-config0 {
				temperature = <125000>;
				hysteresis = <1000>;
				type = "passive";
			};
		};
	};


	cpu_therm {//place to AP IC
		polling-delay-passive = <0>;
		polling-delay = <0>;
		thermal-governor = "user_space";
		thermal-sensors = <&pm6150l_adc_tm ADC_AMUX_THM3_PU2>;
		trips {
			active-config0 {
				temperature = <125000>;
				hysteresis = <1000>;
				type = "passive";
			};
		};
	};

	nvm-therm-adc {
		polling-delay-passive = <0>;
		polling-delay = <0>;
		thermal-governor = "user_space";
		thermal-sensors = <&pm6150l_adc_tm ADC_GPIO4_PU2>;
		trips {
			active-config0 {
				temperature = <125000>;
				hysteresis = <1000>;
				type = "passive";
			};
		};
	};

	quiet-therm-step {
		disable-thermal-zone;
	};
};

&sdhc_2 {
	cd-gpios = <&tlmm 69 GPIO_ACTIVE_HIGH>;
	status = "ok";
};

&ufshc_mem {
	vccq2-voltage-level = <1800000 1950000>;
	spm-level = <3>;
	rpm-level = <3>;
};
